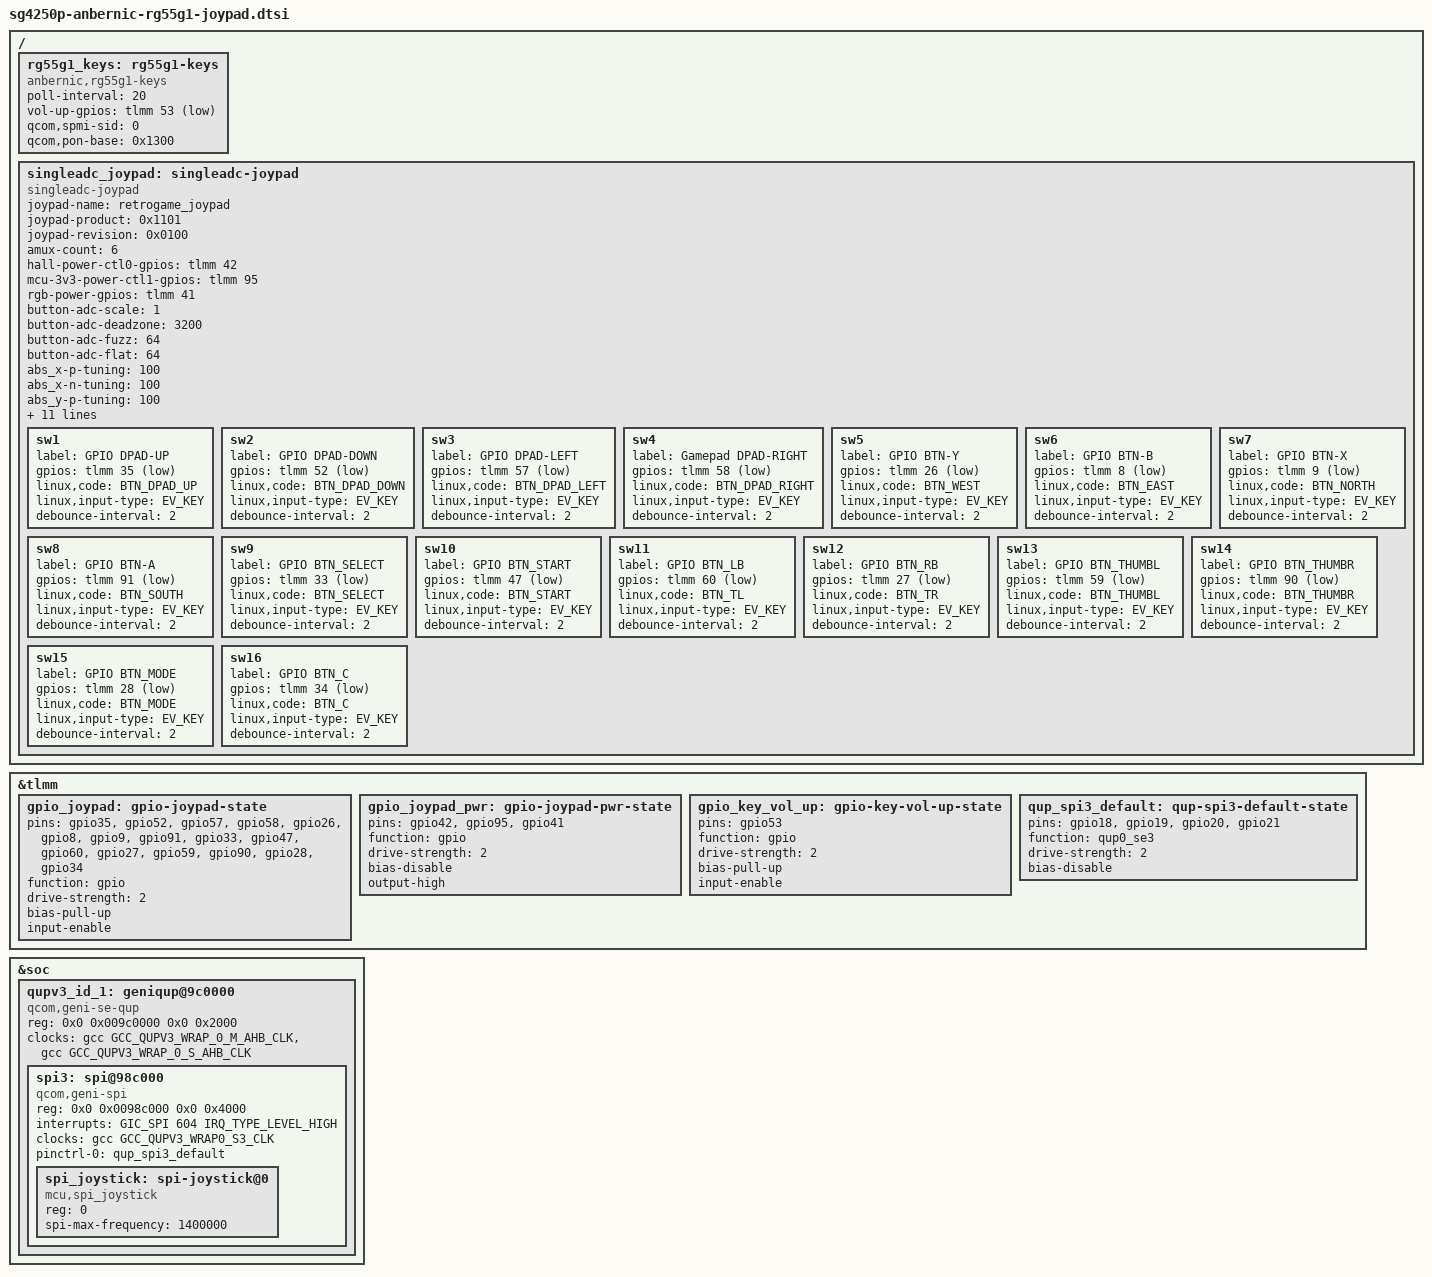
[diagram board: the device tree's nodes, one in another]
// SPDX-License-Identifier: GPL-2.0-only
/*
 * RG55G1 singleadc-joypad + power/volume keys (mainline labels).
 */
#include <dt-bindings/gpio/gpio.h>
#include <dt-bindings/input/linux-event-codes.h>

&tlmm {
	gpio_joypad: gpio-joypad-state {
		pins = "gpio35", "gpio52", "gpio57", "gpio58",
		       "gpio26", "gpio8", "gpio9", "gpio91",
		       "gpio33", "gpio47", "gpio60", "gpio27",
		       "gpio59", "gpio90", "gpio28", "gpio34";
		function = "gpio";
		drive-strength = <2>;
		bias-pull-up;
		input-enable;
	};

	gpio_joypad_pwr: gpio-joypad-pwr-state {
		pins = "gpio42", "gpio95", "gpio41";
		function = "gpio";
		drive-strength = <2>;
		bias-disable;
		output-high;
	};

	gpio_key_vol_up: gpio-key-vol-up-state {
		pins = "gpio53";
		function = "gpio";
		drive-strength = <2>;
		bias-pull-up;
		input-enable;
	};

	qup_spi3_default: qup-spi3-default-state {
		pins = "gpio18", "gpio19", "gpio20", "gpio21";
		function = "qup0_se3";
		drive-strength = <2>;
		bias-disable;
	};
};

/*
 * QUPV3 wrap0 @ 0x9c0000 — SPI SE3 for MCU analog sticks.
 * (Mainline sm4450.dtsi only has wrap1 uart7; add wrap0 here.)
 */
&soc {
	qupv3_id_1: geniqup@9c0000 {
		compatible = "qcom,geni-se-qup";
		reg = <0x0 0x009c0000 0x0 0x2000>;
		ranges;
		clocks = <&gcc GCC_QUPV3_WRAP_0_M_AHB_CLK>,
			 <&gcc GCC_QUPV3_WRAP_0_S_AHB_CLK>;
		clock-names = "m-ahb", "s-ahb";
		#address-cells = <2>;
		#size-cells = <2>;
		status = "okay";

		spi3: spi@98c000 {
			compatible = "qcom,geni-spi";
			reg = <0x0 0x0098c000 0x0 0x4000>;
			#address-cells = <1>;
			#size-cells = <0>;
			interrupts = <GIC_SPI 604 IRQ_TYPE_LEVEL_HIGH>;
			clocks = <&gcc GCC_QUPV3_WRAP0_S3_CLK>;
			clock-names = "se";
			pinctrl-0 = <&qup_spi3_default>;
			pinctrl-names = "default";
			status = "okay";

			spi_joystick: spi-joystick@0 {
				compatible = "mcu,spi_joystick";
				reg = <0>;
				spi-max-frequency = <1400000>;
			};
		};
	};

};

/ {
	rg55g1_keys: rg55g1-keys {
		compatible = "anbernic,rg55g1-keys";
		status = "okay";
		poll-interval = <20>;
		vol-up-gpios = <&tlmm 53 GPIO_ACTIVE_LOW>;
		qcom,spmi-sid = <0>;
		qcom,pon-base = <0x1300>;
	};

	singleadc_joypad: singleadc-joypad {
		compatible = "singleadc-joypad";
		status = "okay";
		/* Match stock / ES autoconfig (retrogame_joypad GUID). */
		joypad-name = "retrogame_joypad";
		joypad-product = <0x1101>;
		joypad-revision = <0x0100>;
		amux-count = <6>;
		hall-power-ctl0-gpios = <&tlmm 42 GPIO_ACTIVE_HIGH>;
		mcu-3v3-power-ctl1-gpios = <&tlmm 95 GPIO_ACTIVE_HIGH>;
		rgb-power-gpios = <&tlmm 41 GPIO_ACTIVE_HIGH>;
		button-adc-scale = <1>;
		button-adc-deadzone = <3200>;
		button-adc-fuzz = <64>;
		button-adc-flat = <64>;
		abs_x-p-tuning = <100>;
		abs_x-n-tuning = <100>;
		abs_y-p-tuning = <100>;
		abs_y-n-tuning = <100>;
		abs_rx-p-tuning = <100>;
		abs_rx-n-tuning = <100>;
		abs_ry-p-tuning = <100>;
		abs_ry-n-tuning = <100>;
		abs_z-p-tuning = <200>;
		abs_z-n-tuning = <200>;
		abs_rz-p-tuning = <200>;
		abs_rz-n-tuning = <200>;
		poll-interval = <10>;
		pinctrl-names = "default";
		pinctrl-0 = <&gpio_joypad &gpio_joypad_pwr>;

		/* BTN_DPAD_* — match retrogame_joypad / RetroArch / ROCKNIX. */
		sw1 {
			label = "GPIO DPAD-UP";
			gpios = <&tlmm 35 GPIO_ACTIVE_LOW>;
			linux,code = <BTN_DPAD_UP>;
			linux,input-type = <EV_KEY>;
			debounce-interval = <2>;
		};
		sw2 {
			label = "GPIO DPAD-DOWN";
			gpios = <&tlmm 52 GPIO_ACTIVE_LOW>;
			linux,code = <BTN_DPAD_DOWN>;
			linux,input-type = <EV_KEY>;
			debounce-interval = <2>;
		};
		sw3 {
			label = "GPIO DPAD-LEFT";
			gpios = <&tlmm 57 GPIO_ACTIVE_LOW>;
			linux,code = <BTN_DPAD_LEFT>;
			linux,input-type = <EV_KEY>;
			debounce-interval = <2>;
		};
		sw4 {
			label = "Gamepad DPAD-RIGHT";
			gpios = <&tlmm 58 GPIO_ACTIVE_LOW>;
			linux,code = <BTN_DPAD_RIGHT>;
			linux,input-type = <EV_KEY>;
			debounce-interval = <2>;
		};
		sw5 {
			label = "GPIO BTN-Y";
			gpios = <&tlmm 26 GPIO_ACTIVE_LOW>;
			linux,code = <BTN_WEST>;
			linux,input-type = <EV_KEY>;
			debounce-interval = <2>;
		};
		sw6 {
			label = "GPIO BTN-B";
			gpios = <&tlmm 8 GPIO_ACTIVE_LOW>;
			linux,code = <BTN_EAST>;
			linux,input-type = <EV_KEY>;
			debounce-interval = <2>;
		};
		sw7 {
			label = "GPIO BTN-X";
			gpios = <&tlmm 9 GPIO_ACTIVE_LOW>;
			linux,code = <BTN_NORTH>;
			linux,input-type = <EV_KEY>;
			debounce-interval = <2>;
		};
		sw8 {
			label = "GPIO BTN-A";
			gpios = <&tlmm 91 GPIO_ACTIVE_LOW>;
			linux,code = <BTN_SOUTH>;
			linux,input-type = <EV_KEY>;
			debounce-interval = <2>;
		};
		sw9 {
			label = "GPIO BTN_SELECT";
			gpios = <&tlmm 33 GPIO_ACTIVE_LOW>;
			linux,code = <BTN_SELECT>;
			linux,input-type = <EV_KEY>;
			debounce-interval = <2>;
		};
		sw10 {
			label = "GPIO BTN_START";
			gpios = <&tlmm 47 GPIO_ACTIVE_LOW>;
			linux,code = <BTN_START>;
			linux,input-type = <EV_KEY>;
			debounce-interval = <2>;
		};
		sw11 {
			label = "GPIO BTN_LB";
			gpios = <&tlmm 60 GPIO_ACTIVE_LOW>;
			linux,code = <BTN_TL>;
			linux,input-type = <EV_KEY>;
			debounce-interval = <2>;
		};
		sw12 {
			label = "GPIO BTN_RB";
			gpios = <&tlmm 27 GPIO_ACTIVE_LOW>;
			linux,code = <BTN_TR>;
			linux,input-type = <EV_KEY>;
			debounce-interval = <2>;
		};
		sw13 {
			label = "GPIO BTN_THUMBL";
			gpios = <&tlmm 59 GPIO_ACTIVE_LOW>;
			linux,code = <BTN_THUMBL>;
			linux,input-type = <EV_KEY>;
			debounce-interval = <2>;
		};
		sw14 {
			label = "GPIO BTN_THUMBR";
			gpios = <&tlmm 90 GPIO_ACTIVE_LOW>;
			linux,code = <BTN_THUMBR>;
			linux,input-type = <EV_KEY>;
			debounce-interval = <2>;
		};
		sw15 {
			label = "GPIO BTN_MODE";
			gpios = <&tlmm 28 GPIO_ACTIVE_LOW>;
			linux,code = <BTN_MODE>;
			linux,input-type = <EV_KEY>;
			debounce-interval = <2>;
		};
		sw16 {
			label = "GPIO BTN_C";
			gpios = <&tlmm 34 GPIO_ACTIVE_LOW>;
			linux,code = <BTN_C>;
			linux,input-type = <EV_KEY>;
			debounce-interval = <2>;
		};
	};
};
